# STM32WB30_CM4 register map
File version: 1.4-IAR
CPU: CM4 r0p1, little endian, MPU, FPU, 4 interrupt priority bits
Registers are 32-bit, read-write, reset 0x0 unless marked. A register's access mark holds for its fields unless they carry their own. Offsets are from the block's base; [hi:lo] are bit positions; {n}, {i} and the like mark numbered series; 'fields as' and 'values as' point back to an identical list.

## GPIOH — General-purpose I/Os
Base 0x48001C00
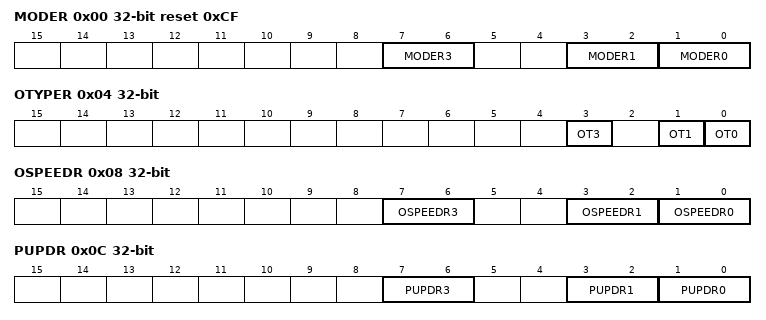
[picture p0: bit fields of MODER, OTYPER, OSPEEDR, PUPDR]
0x00 MODER reset 0xCF — GPIO port mode register
  [7:6] MODER3 — Port x configuration bits (y = 0..15)
  [3:2] MODER1 — Port x configuration bits (y = 0..15)
  [1:0] MODER0 — Port x configuration bits (y = 0..15)
0x04 OTYPER — GPIO port output type register
  [3] OT3 — Port x configuration bits (y = 0..15)
  [1] OT1 — Port x configuration bits (y = 0..15)
  [0] OT0 — Port x configuration bits (y = 0..15)
0x08 OSPEEDR — GPIO port output speed register
  [7:6] OSPEEDR3 — Port x configuration bits (y = 0..15)
  [3:2] OSPEEDR1 — Port x configuration bits (y = 0..15)
  [1:0] OSPEEDR0 — Port x configuration bits (y = 0..15)
0x0C PUPDR — GPIO port pull-up/pull-down register
  [7:6] PUPDR3 — Port x configuration bits (y = 0..15)
  [3:2] PUPDR1 — Port x configuration bits (y = 0..15)
  [1:0] PUPDR0 — Port x configuration bits (y = 0..15)
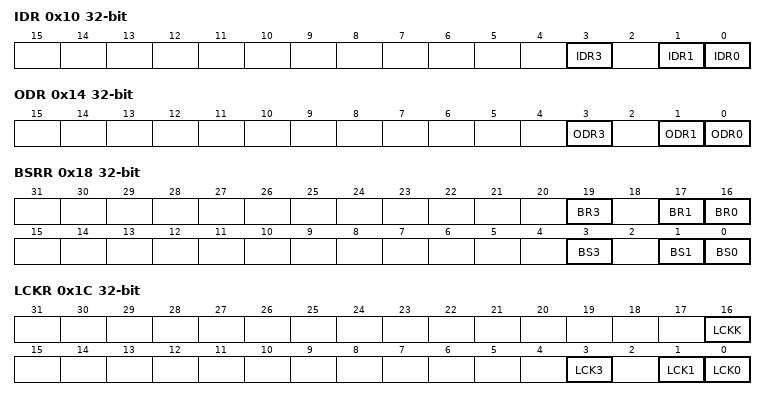
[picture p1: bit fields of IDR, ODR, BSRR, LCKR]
0x10 IDR ro — GPIO port input data register
  [3] IDR3 — Port input data (y = 0..15)
  [1] IDR1 — Port input data (y = 0..15)
  [0] IDR0 — Port input data (y = 0..15)
0x14 ODR — GPIO port output data register
  [3] ODR3 — Port output data (y = 0..15)
  [1] ODR1 — Port output data (y = 0..15)
  [0] ODR0 — Port output data (y = 0..15)
0x18 BSRR wo — GPIO port bit set/reset register
  [19] BR3 — Port x reset bit y (y = 0..15)
  [17] BR1 — Port x reset bit y (y = 0..15)
  [16] BR0 — Port x set bit y (y= 0..15)
  [3] BS3 — Port x set bit y (y= 0..15)
  [1] BS1 — Port x set bit y (y= 0..15)
  [0] BS0 — Port x set bit y (y= 0..15)
0x1C LCKR — GPIO port configuration lock register
  [16] LCKK — Port x lock bit y (y= 0..15)
  [3] LCK3 — Port x lock bit y (y= 0..15)
  [1] LCK1 — Port x lock bit y (y= 0..15)
  [0] LCK0 — Port x lock bit y (y= 0..15)
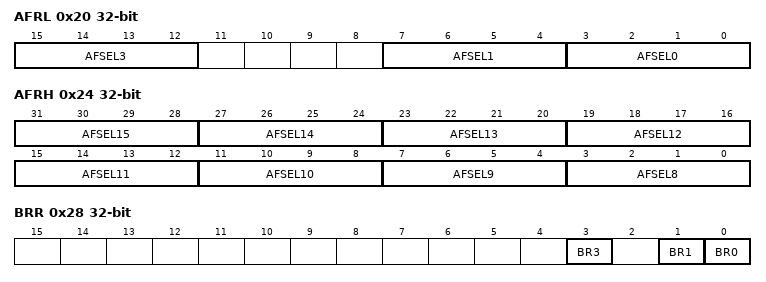
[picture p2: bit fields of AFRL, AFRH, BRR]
0x20 AFRL — GPIO alternate function low register
  [15:12] AFSEL3 — Alternate function selection for port x bit y (y = 0..7)
  [7:4] AFSEL1 — Alternate function selection for port x bit y (y = 0..7)
  [3:0] AFSEL0 — Alternate function selection for port x bit y (y = 0..7)
0x24 AFRH — GPIO alternate function high register
  [4n-29:4n-32] AFSEL{n} (n=8..15) — Alternate function selection for port x bit y (y = 8..15)
0x28 BRR wo — port bit reset register
  [3] BR3 — Port Reset bit
  [1] BR1 — Port Reset bit
  [0] BR0 — Port Reset bit

## HSEM
Base 0x58001400
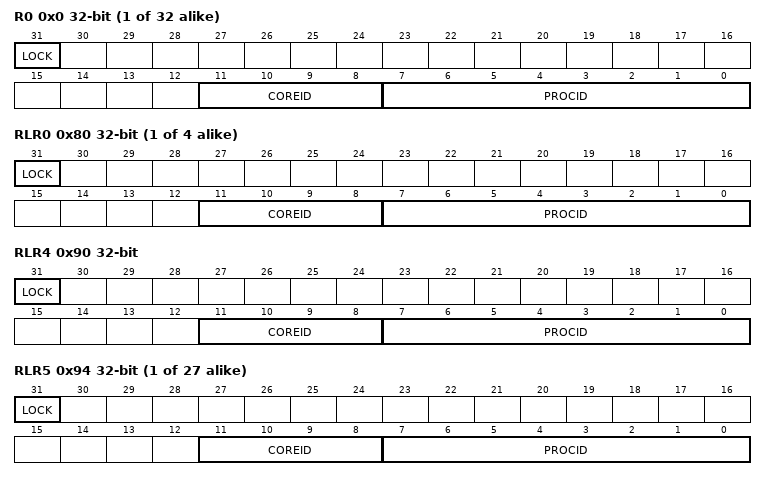
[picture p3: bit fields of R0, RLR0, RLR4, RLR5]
{0x0+4i} R{i} (i=0..31) — Semaphore {i} register
  [31] LOCK — lock indication
  [11:8] COREID — Semaphore CoreID
  [7:0] PROCID — Semaphore ProcessID
{0x80+4i} RLR{i} ro (i=0..3) — Semaphore {i} read lock register
  fields as R0
0x90 RLR4 ro — Semaphore 4 read lock read lock register
  fields as R0
{0x80+4i} RLR{i} ro (i=5..31) — Semaphore {i} read lock register
  fields as R0
0x100 C1IER0 — HSEM Interrupt enable register
  [31:0] ISEm — CPU(n) semaphore m enable bit
0x104 C1ICR — HSEM Interrupt clear register
  [31:0] ISCm — CPU(n) semaphore m clear bit
0x108 C1ISR ro — HSEM Interrupt status register
  [31:0] ISFm — CPU(n) semaphore m status bit before enable (mask)
0x10C C1MISR ro — HSEM Masked interrupt status register
  [31:0] MISFm — masked CPU(n) semaphore m status bit after enable (mask).
0x110 C2IER0 — HSEM Interrupt enable register
  [31:0] ISEm — CPU(2) semaphore m enable bit.
0x114 C2ICR — HSEM Interrupt clear register
  [31:0] ISCm — CPU(2) semaphore m clear bit
0x118 C2ISR ro — HSEM Interrupt status register
  [31:0] ISFm — CPU(2) semaphore m status bit before enable (mask).
0x11C C2MISR ro — HSEM Masked interrupt status register
  [31:0] MISFm — masked CPU(2) semaphore m status bit after enable (mask).
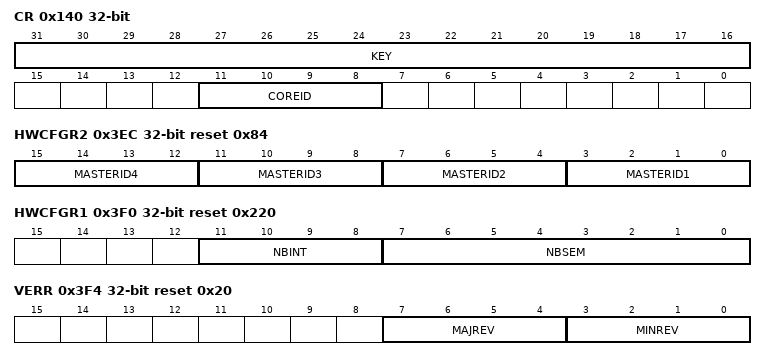
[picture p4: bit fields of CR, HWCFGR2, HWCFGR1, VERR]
0x140 CR — Semaphore Clear register
  [31:16] KEY — Semaphore clear Key
  [11:8] COREID — CoreID of semaphore to be cleared
0x144 KEYR — Interrupt clear register
  [31:16] KEY — Semaphore Clear Key
0x3EC HWCFGR2 ro reset 0x84 — Semaphore hardware configuration register 2
  [4n-1:4n-4] MASTERID{n} (n=1..4) — Hardware Configuration valid bus masters ID{n}
0x3F0 HWCFGR1 ro reset 0x220 — Semaphore hardware configuration register 1
  [11:8] NBINT — Hardware Configuration number of interrupts supported number of master IDs
  [7:0] NBSEM — Hardware Configuration number of semaphores
0x3F4 VERR ro reset 0x20 — HSEM version register
  [7:4] MAJREV — Major Revision
  [3:0] MINREV — Minor Revision
0x3F8 IPIDR ro reset 0x100072 — HSEM indentification register
  [31:0] ID — Identification Code
0x3FC SIDR ro reset 0xA3C5DD01 — HSEM size indentification register
  [31:0] SID — Size Identification Code
